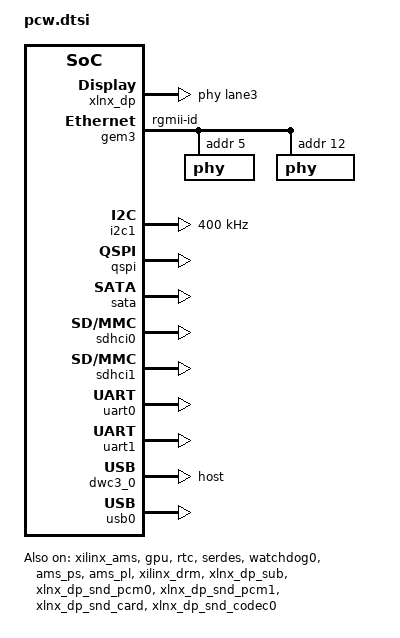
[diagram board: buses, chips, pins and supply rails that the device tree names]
/*
 * CAUTION: This file is automatically generated by Xilinx.
 * Version:  
 * Today is: Mon Jul  3 14:17:05 2017
*/


&lpd_dma_chan1 {
	status = "okay";
};
&lpd_dma_chan2 {
	status = "okay";
};
&lpd_dma_chan3 {
	status = "okay";
};
&lpd_dma_chan4 {
	status = "okay";
};
&lpd_dma_chan5 {
	status = "okay";
};
&lpd_dma_chan6 {
	status = "okay";
};
&lpd_dma_chan7 {
	status = "okay";
};
&lpd_dma_chan8 {
	status = "okay";
};
&xilinx_ams {
	status = "okay";
};
&xlnx_dp {
	phy-names = "dp-phy0","dp-phy1";
	phys = <&lane3 5 0 3 27000000>,
		<&lane2 5 1 3 27000000>;
	status = "okay";
	xlnx,max-lanes = <2>;
};
&xlnx_dpdma {
	status = "okay";
};
&gem3 {
	phy-mode = "rgmii-id";
	status = "okay";
	xlnx,ptp-enet-clock = <0x0>;
	local-mac-address = [00 0a 35 00 22 01];

			phy@5 {
				reg = <0x5>;
				ti,rx-internal-delay = <0x5>;
				ti,tx-internal-delay = <0x5>;
				ti,fifo-depth = <0x1>;
			};

			phy@c {
				reg = <0xc>;
				ti,rx-internal-delay = <0x8>;
				ti,tx-internal-delay = <0xa>;
				ti,fifo-depth = <0x1>;
			};
};
&fpd_dma_chan1 {
	status = "okay";
};
&fpd_dma_chan2 {
	status = "okay";
};
&fpd_dma_chan3 {
	status = "okay";
};
&fpd_dma_chan4 {
	status = "okay";
};
&fpd_dma_chan5 {
	status = "okay";
};
&fpd_dma_chan6 {
	status = "okay";
};
&fpd_dma_chan7 {
	status = "okay";
};
&fpd_dma_chan8 {
	status = "okay";
};
&gpio {
	emio-gpio-width = <32>;
	gpio-mask-high = <0x0>;
	gpio-mask-low = <0x5600>;
	status = "okay";
};
&gpu {
	status = "okay";
};
&i2c1 {
	clock-frequency = <400000>;
	status = "okay";
};
&pinctrl0 {
	status = "okay";
};
&qspi {
	is-dual = <1>;
	num-cs = <1>;
	status = "okay";
};
&rtc {
	status = "okay";
};
&sata {
	status = "okay";
};
&sdhci0 {
	clock-frequency = <199998000>;
	status = "okay";
	xlnx,mio_bank = <0x0>;
};
&sdhci1 {
	clock-frequency = <199998000>;
	status = "okay";
	xlnx,mio_bank = <0x1>;
	no-1-8-v;
};
&serdes {
	status = "okay";
};
&uart0 {
	device_type = "serial";
	port-number = <0>;
	status = "okay";
	u-boot,dm-pre-reloc ;
};
&uart1 {
	device_type = "serial";
	port-number = <1>;
	status = "okay";
	u-boot,dm-pre-reloc ;
};
&dwc3_0 {
	dr_mode = "host";
 	status = "okay";
};
&watchdog0 {
	status = "okay";
};
&ams_ps {
	status = "okay";
};
&ams_pl {
	status = "okay";
};
&xilinx_drm {
	status = "okay";
};
&xlnx_dp_sub {
	status = "okay";
};
&xlnx_dp_snd_pcm0 {
	status = "okay";
};
&xlnx_dp_snd_pcm1 {
	status = "okay";
};
&xlnx_dp_snd_card {
	status = "okay";
};
&xlnx_dp_snd_codec0 {
	status = "okay";
};
&usb0 {
	status = "okay";
};
